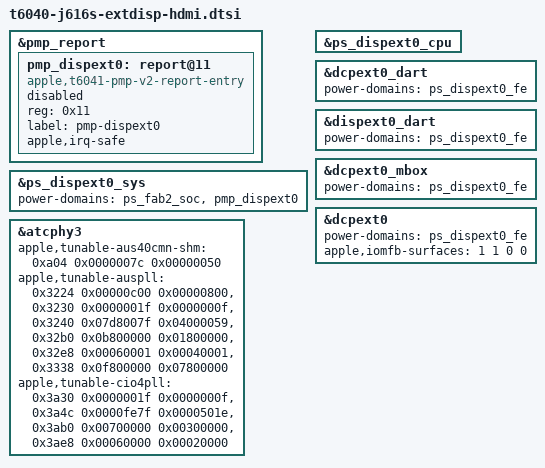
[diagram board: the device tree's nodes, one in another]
// SPDX-License-Identifier: GPL-2.0+ OR MIT
/*
 * The fixed HDMI path of t6040-j616s-extdisp.dtsi (dcpext0 -> atc3 crossbar
 * -> atcphy3 -> DP-to-HDMI converter) with every node left DISABLED. The
 * nodes must not be enabled at boot in the device tree: powering the DISPEXT
 * chain without the PMP acknowledgement hangs the machine before root. The
 * enable gate (drivers/soc/apple/display-gate.c) switches them on in
 * order once the PMP is bound.
 *
 * dispext0's DART is not in the display node's iommus: the gate appends it
 * when it enables the chain, so the internal display's DART domain stays as
 * it is without the external displays.
 */

/*
 * DISPEXT0 may only be powered once the PMP has acknowledged it in its
 * device-state table (SOC-DEV-PS-REQ/ACK, PTD entries 480/488 on T6041):
 * its ADT iop-pmp-nub soc-device ID is 18, so its request bit is 17.
 * Without it, enabling the DISPEXT0 PMGR chain hung the machine before
 * root. The T6030 PMP device-state provider works the same way.
 */
&pmp_report {
	pmp_dispext0: report@11 {
		compatible = "apple,t6041-pmp-v2-report-entry",
			     "apple,t6000-pmp-v2-report-entry";
		reg = <0x11>;
		label = "pmp-dispext0";
		#power-domain-cells = <0>;
		/* parent of the IRQ-safe PMGR chain */
		apple,irq-safe;
		status = "disabled";
	};
};

/* ADT DISPEXT0_SYS parents: FAB2_SOC and the DISPEXT rail (PMP request). */
&ps_dispext0_sys {
	power-domains = <&ps_fab2_soc>, <&pmp_dispext0>;
};

&ps_dispext0_cpu {
	/*
	 * NEVER enable: the ADT marks DISPEXT0_CPU no_ps (no PMGR power-state
	 * register, like the internal DISP_CPU). Its probe reads offset 0x350,
	 * and that read resets the SoC. DCPEXT0's own power gate (ADT power-gates 431) is the
	 * virtual DISPEXT0-CPU-V; the last real register of the chain is FE.
	 */
	/delete-property/ apple,always-on;
};

&dcpext0_dart {
	/* in the DISPEXT0 block: powered (after the PMP request) before probing */
	power-domains = <&ps_dispext0_fe>;
};

&dispext0_dart {
	/* in the DISPEXT0 block: powered (after the PMP request) before probing */
	power-domains = <&ps_dispext0_fe>;
};

&dcpext0_mbox {
	power-domains = <&ps_dispext0_fe>;
};

&dcpext0 {
	power-domains = <&ps_dispext0_fe>;
	/*
	 * The IOMFB surface layout of the internal DCP;
	 * without apple,iomfb-surfaces apple-dcp's probe fails with -EINVAL.
	 */
	apple,iomfb-surfaces = <1 1 0 0>;
};

/*
 * atcphy3 apply_tunables tables (aciophy_phy_init mode 3), from this machine's ADT /arm-io/atc-phy3
 * (privateartifacts/omarchy-m4-unit/adt.bin): AXI2AF converted entry by entry; every other table is
 * byte-identical to atc-phy0 in the ADT, so the atcphy0 values of t6040-j616s-usb3.dtsi are reused
 * (AUS40CMN_SHM differs: 0x50). Only the first six (axi2af..lane1) are applied in DP mode; those
 * are in t604x-extdisp.dtsi, as J616c has the same values.
 */
&atcphy3 {
	apple,tunable-aus40cmn-shm =
		<0xa04 0x0000007c 0x00000050>;
	apple,tunable-auspll =
		<0x3224 0x00000c00 0x00000800>,
		<0x3230 0x0000001f 0x0000000f>,
		<0x3240 0x07d8007f 0x04000059>,
		<0x32b0 0x0b800000 0x01800000>,
		<0x32e8 0x00060001 0x00040001>,
		<0x3338 0x0f800000 0x07800000>;
	apple,tunable-cio4pll =
		<0x3a30 0x0000001f 0x0000000f>,
		<0x3a4c 0x0000fe7f 0x0000501e>,
		<0x3ab0 0x00700000 0x00300000>,
		<0x3ae8 0x00060000 0x00020000>;
};
